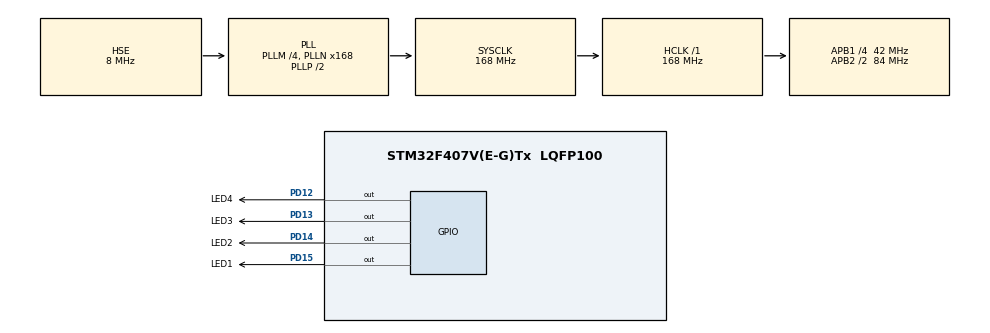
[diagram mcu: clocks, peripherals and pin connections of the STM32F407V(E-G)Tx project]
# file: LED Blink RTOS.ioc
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FREERTOS.Tasks01=LED1Task,0,128,LED1_Task,Default,NULL,Dynamic,NULL,NULL;LED2Task,0,128,LED2_Tak,Default,NULL,Dynamic,NULL,NULL;LED3Task,0,128,LED3_Task,Default,NULL,Dynamic,NULL,NULL;LED4Task,0,128,LED4_Task,Default,NULL,Dynamic,NULL,NULL
FREERTOS.configTOTAL_HEAP_SIZE=15360
Mcu.Family=STM32F4
Mcu.Name=STM32F407V(E-G)Tx
Mcu.Package=LQFP100
NVIC.PriorityGroup=NVIC_PRIORITYGROUP_4
NVIC.TIM6_DAC_IRQn=true\:0\:0\:false\:false\:true\:false\:false\:true
NVIC.TimeBase=TIM6_DAC_IRQn
NVIC.TimeBaseIP=TIM6
PD12.GPIO_Label=LED4
PD12.Signal=GPIO_Output
PD13.GPIO_Label=LED3
PD13.Signal=GPIO_Output
PD14.GPIO_Label=LED2
PD14.Signal=GPIO_Output
PD15.GPIO_Label=LED1
PD15.Signal=GPIO_Output
PH0-OSC_IN.Mode=HSE-External-Oscillator
PH0-OSC_IN.Signal=RCC_OSC_IN
PH1-OSC_OUT.Mode=HSE-External-Oscillator
PH1-OSC_OUT.Signal=RCC_OSC_OUT
ProjectManager.HeapSize=0x200
ProjectManager.StackSize=0x400
ProjectManager.TargetToolchain=STM32CubeIDE
RCC.48MHZClocksFreq_Value=84000000
RCC.AHBFreq_Value=168000000
RCC.APB1CLKDivider=RCC_HCLK_DIV4
RCC.APB1Freq_Value=42000000
RCC.APB1TimFreq_Value=84000000
RCC.APB2CLKDivider=RCC_HCLK_DIV2
RCC.APB2Freq_Value=84000000
RCC.APB2TimFreq_Value=168000000
RCC.CortexFreq_Value=168000000
RCC.HCLKFreq_Value=168000000
RCC.HSE_VALUE=8000000
RCC.HSI_VALUE=16000000
RCC.LSE_VALUE=32768
RCC.PLLM=4
RCC.PLLN=168
RCC.PLLSourceVirtual=RCC_PLLSOURCE_HSE
RCC.SYSCLKFreq_VALUE=168000000
RCC.SYSCLKSource=RCC_SYSCLKSOURCE_PLLCLK
RCC.VCOOutputFreq_Value=336000000
VP_FREERTOS_VS_CMSIS_V1.Mode=CMSIS_V1
VP_SYS_VS_tim6.Mode=TIM6
board=custom

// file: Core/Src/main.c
/* USER CODE BEGIN Header */
/**
  ******************************************************************************
  * @file           : main.c
  * @brief          : Main program body
  ******************************************************************************
  * @attention
  *
  * <h2><center>&copy; Copyright (c) 2021 STMicroelectronics.
  * All rights reserved.</center></h2>
  *
  * This software component is licensed by ST under BSD 3-Clause license,
  * the "License"; You may not use this file except in compliance with the
  * License. You may obtain a copy of the License at:
  *                        opensource.org/licenses/BSD-3-Clause
  *
  ******************************************************************************
  */
/* USER CODE END Header */
#include "main.h"
#include "cmsis_os.h"
#include "gpio.h"

void SystemClock_Config(void);
void MX_FREERTOS_Init(void);

int main(void)
{

  /* MCU Configuration--------------------------------------------------------*/

  /* Reset of all peripherals, Initializes the Flash interface and the Systick. */
  HAL_Init();

  /* Configure the system clock */
  SystemClock_Config();

  /* Initialize all configured peripherals */
  MX_GPIO_Init();

  /* Call init function for freertos objects (in freertos.c) */
  MX_FREERTOS_Init();
  /* Start scheduler */
  osKernelStart();

  /* We should never get here as control is now taken by the scheduler */
  /* Infinite loop */
  while (1)
  {

  }
}

void SystemClock_Config(void)
{
  RCC_OscInitTypeDef RCC_OscInitStruct = {0};
  RCC_ClkInitTypeDef RCC_ClkInitStruct = {0};

  /** Configure the main internal regulator output voltage
  */
  __HAL_RCC_PWR_CLK_ENABLE();
  __HAL_PWR_VOLTAGESCALING_CONFIG(PWR_REGULATOR_VOLTAGE_SCALE1);
  /** Initializes the RCC Oscillators according to the specified parameters
  * in the RCC_OscInitTypeDef structure.
  */
  RCC_OscInitStruct.OscillatorType = RCC_OSCILLATORTYPE_HSE;
  RCC_OscInitStruct.HSEState = RCC_HSE_ON;
  RCC_OscInitStruct.PLL.PLLState = RCC_PLL_ON;
  RCC_OscInitStruct.PLL.PLLSource = RCC_PLLSOURCE_HSE;
  RCC_OscInitStruct.PLL.PLLM = 4;
  RCC_OscInitStruct.PLL.PLLN = 168;
  RCC_OscInitStruct.PLL.PLLP = RCC_PLLP_DIV2;
  RCC_OscInitStruct.PLL.PLLQ = 4;
  if (HAL_RCC_OscConfig(&RCC_OscInitStruct) != HAL_OK)
  {
    Error_Handler();
  }
  /** Initializes the CPU, AHB and APB buses clocks
  */
  RCC_ClkInitStruct.ClockType = RCC_CLOCKTYPE_HCLK|RCC_CLOCKTYPE_SYSCLK
                              |RCC_CLOCKTYPE_PCLK1|RCC_CLOCKTYPE_PCLK2;
  RCC_ClkInitStruct.SYSCLKSource = RCC_SYSCLKSOURCE_PLLCLK;
  RCC_ClkInitStruct.AHBCLKDivider = RCC_SYSCLK_DIV1;
  RCC_ClkInitStruct.APB1CLKDivider = RCC_HCLK_DIV4;
  RCC_ClkInitStruct.APB2CLKDivider = RCC_HCLK_DIV2;

  if (HAL_RCC_ClockConfig(&RCC_ClkInitStruct, FLASH_LATENCY_5) != HAL_OK)
  {
    Error_Handler();
  }
}

 /**
  * @brief  Period elapsed callback in non blocking mode
  * @note   This function is called  when TIM6 interrupt took place, inside
  * HAL_TIM_IRQHandler(). It makes a direct call to HAL_IncTick() to increment
  * a global variable "uwTick" used as application time base.
  * @param  htim : TIM handle
  * @retval None
  */
void HAL_TIM_PeriodElapsedCallback(TIM_HandleTypeDef *htim)
{
  if (htim->Instance == TIM6) {
    HAL_IncTick();
  }
}

void Error_Handler(void)
{
  __disable_irq();
  while (1)
  {
  }
}

/************************ (C) COPYRIGHT STMicroelectronics *****END OF FILE****/

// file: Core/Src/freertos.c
/* USER CODE BEGIN Header */
/**
  ******************************************************************************
  * File Name          : freertos.c
  * Description        : Code for freertos applications
  ******************************************************************************
  * @attention
  *
  * <h2><center>&copy; Copyright (c) 2021 STMicroelectronics.
  * All rights reserved.</center></h2>
  *
  * This software component is licensed by ST under Ultimate Liberty license
  * SLA0044, the "License"; You may not use this file except in compliance with
  * the License. You may obtain a copy of the License at:
  *                             www.st.com/SLA0044
  *
  ******************************************************************************
  */
/* USER CODE END Header */

#include "FreeRTOS.h"
#include "task.h"
#include "main.h"
#include "cmsis_os.h"

osThreadId LED1TaskHandle;
osThreadId LED2TaskHandle;
osThreadId LED3TaskHandle;
osThreadId LED4TaskHandle;

void LED1_Task(void const * argument);
void LED2_Tak(void const * argument);
void LED3_Task(void const * argument);
void LED4_Task(void const * argument);

void MX_FREERTOS_Init(void); /* (MISRA C 2004 rule 8.1) */

/* GetIdleTaskMemory prototype (linked to static allocation support) */
void vApplicationGetIdleTaskMemory( StaticTask_t **ppxIdleTaskTCBBuffer, StackType_t **ppxIdleTaskStackBuffer, uint32_t *pulIdleTaskStackSize );

/* USER CODE BEGIN GET_IDLE_TASK_MEMORY */
static StaticTask_t xIdleTaskTCBBuffer;
static StackType_t xIdleStack[configMINIMAL_STACK_SIZE];

void vApplicationGetIdleTaskMemory( StaticTask_t **ppxIdleTaskTCBBuffer, StackType_t **ppxIdleTaskStackBuffer, uint32_t *pulIdleTaskStackSize )
{
  *ppxIdleTaskTCBBuffer = &xIdleTaskTCBBuffer;
  *ppxIdleTaskStackBuffer = &xIdleStack[0];
  *pulIdleTaskStackSize = configMINIMAL_STACK_SIZE;
  /* place for user code */
}
/* USER CODE END GET_IDLE_TASK_MEMORY */

void MX_FREERTOS_Init(void) {

  /* Create the thread(s) */
  /* definition and creation of LED1Task */
  osThreadDef(LED1Task, LED1_Task, osPriorityNormal, 0, 128);
  LED1TaskHandle = osThreadCreate(osThread(LED1Task), NULL);

  /* definition and creation of LED2Task */
  osThreadDef(LED2Task, LED2_Tak, osPriorityNormal, 0, 128);
  LED2TaskHandle = osThreadCreate(osThread(LED2Task), NULL);

  /* definition and creation of LED3Task */
  osThreadDef(LED3Task, LED3_Task, osPriorityNormal, 0, 128);
  LED3TaskHandle = osThreadCreate(osThread(LED3Task), NULL);

  /* definition and creation of LED4Task */
  osThreadDef(LED4Task, LED4_Task, osPriorityNormal, 0, 128);
  LED4TaskHandle = osThreadCreate(osThread(LED4Task), NULL);

}

void LED1_Task(void const * argument)
{
  /* USER CODE BEGIN LED1_Task */
  /* Infinite loop */

  for(;;)
  {
      HAL_GPIO_TogglePin(LED1_GPIO_Port, LED1_Pin);
	  osDelay(100);
  }
  /* USER CODE END LED1_Task */
}

void LED2_Tak(void const * argument)
{
  /* USER CODE BEGIN LED2_Tak */
  /* Infinite loop */
  for(;;)
  {
      HAL_GPIO_TogglePin(LED2_GPIO_Port, LED2_Pin);
	  osDelay(500);
  }
  /* USER CODE END LED2_Tak */
}

void LED3_Task(void const * argument)
{
  /* USER CODE BEGIN LED3_Task */
  /* Infinite loop */
  for(;;)
  {
      HAL_GPIO_TogglePin(LED3_GPIO_Port, LED3_Pin);
    osDelay(1000);
  }
  /* USER CODE END LED3_Task */
}

void LED4_Task(void const * argument)
{
  /* USER CODE BEGIN LED4_Task */
  /* Infinite loop */
  for(;;)
  {
      HAL_GPIO_TogglePin(LED4_GPIO_Port, LED4_Pin);
	  osDelay(50);
  }
  /* USER CODE END LED4_Task */
}

/************************ (C) COPYRIGHT STMicroelectronics *****END OF FILE****/
